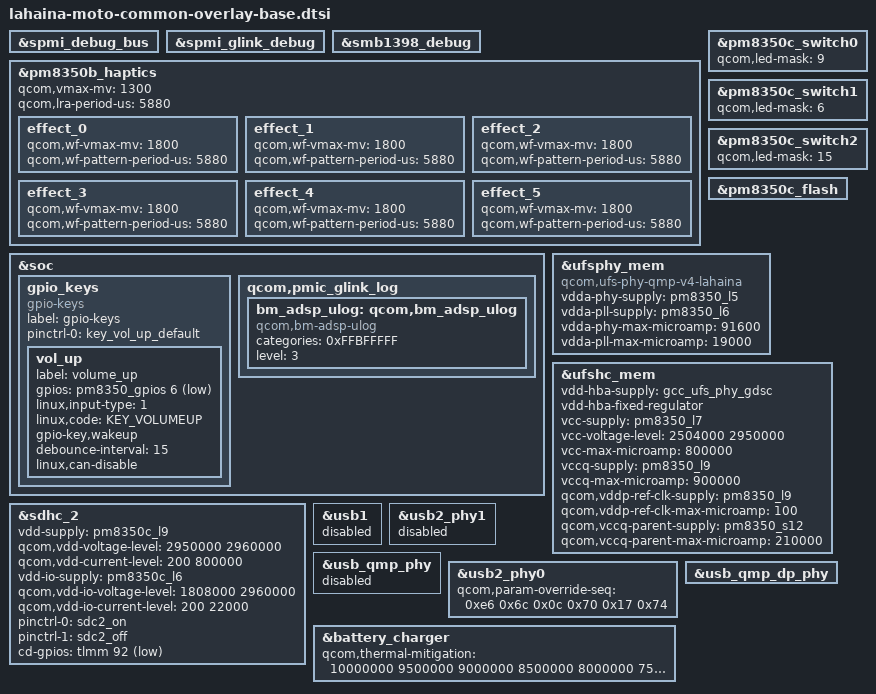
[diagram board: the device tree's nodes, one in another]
/* Copyright (c) 2020, The Linux Foundation. All rights reserved.
 *
 * This program is free software; you can redistribute it and/or modify
 * it under the terms of the GNU General Public License version 2 and
 * only version 2 as published by the Free Software Foundation.
 *
 * This program is distributed in the hope that it will be useful,
 * but WITHOUT ANY WARRANTY; without even the implied warranty of
 * MERCHANTABILITY or FITNESS FOR A PARTICULAR PURPOSE.  See the
 * GNU General Public License for more details.
 */

#include <dt-bindings/gpio/gpio.h>
#include <dt-bindings/input/input.h>

#include "lahaina-pmic-overlay.dtsi"
#include "lahaina-thermal-overlay.dtsi"

&spmi_debug_bus {
	status = "ok";
};

&spmi_glink_debug {
	status = "ok";
};

&smb1398_debug {
	status = "ok";
};

&pm8350b_haptics {
	qcom,vmax-mv = <1300>;
	qcom,lra-period-us = <5880>;
	status = "ok";

	effect_0 {
		/* CLICK */
		qcom,wf-vmax-mv = <1800>;
		qcom,wf-pattern-period-us = <5880>;
	};

	effect_1 {
		/* DOUBLE_CLICK */
		qcom,wf-vmax-mv = <1800>;
		qcom,wf-pattern-period-us = <5880>;
	};

	effect_2 {
		/* TICK */
		qcom,wf-vmax-mv = <1800>;
		qcom,wf-pattern-period-us = <5880>;
	};

	effect_3 {
		/* THUD */
		qcom,wf-vmax-mv = <1800>;
		qcom,wf-pattern-period-us = <5880>;
	};

	effect_4 {
		/* POP */
		qcom,wf-vmax-mv = <1800>;
		qcom,wf-pattern-period-us = <5880>;
	};

	effect_5 {
		/* HEAVY CLICK */
		qcom,wf-vmax-mv = <1800>;
		qcom,wf-pattern-period-us = <5880>;
	};
};

&soc {
	gpio_keys {
		compatible = "gpio-keys";
		label = "gpio-keys";

		pinctrl-names = "default";
		pinctrl-0 = <&key_vol_up_default>;

		vol_up {
			label = "volume_up";
			gpios = <&pm8350_gpios 6 GPIO_ACTIVE_LOW>;
			linux,input-type = <1>;
			linux,code = <KEY_VOLUMEUP>;
			gpio-key,wakeup;
			debounce-interval = <15>;
			linux,can-disable;
		};
	};

       qcom,pmic_glink_log {
               bm_adsp_ulog: qcom,bm_adsp_ulog {
                       compatible = "qcom,bm-adsp-ulog";
                       categories = <0xFFBFFFFF>;
                       level = <3>;
               };
       };

};

&pm8350c_switch0 {
	qcom,led-mask = <9>; /* Channels 1 & 4 */
};

&pm8350c_switch1 {
	qcom,led-mask = <6>; /* Channels 2 & 3 */
};

&pm8350c_switch2 {
	qcom,led-mask = <15>; /* All Channels */
};

&pm8350c_flash {
	status = "ok";
};

&ufsphy_mem {
	compatible = "qcom,ufs-phy-qmp-v4-lahaina";

	vdda-phy-supply = <&pm8350_l5>;
	vdda-pll-supply = <&pm8350_l6>;
	vdda-phy-max-microamp = <91600>;
	vdda-pll-max-microamp = <19000>;

	status = "ok";
};

&ufshc_mem {
	vdd-hba-supply = <&gcc_ufs_phy_gdsc>;
	vdd-hba-fixed-regulator;

	vcc-supply = <&pm8350_l7>;
	vcc-voltage-level = <2504000 2950000>;
	vcc-max-microamp = <800000>;

	vccq-supply = <&pm8350_l9>;
	vccq-max-microamp = <900000>;

	qcom,vddp-ref-clk-supply = <&pm8350_l9>;
	qcom,vddp-ref-clk-max-microamp = <100>;

	qcom,vccq-parent-supply = <&pm8350_s12>;
	qcom,vccq-parent-max-microamp = <210000>;

	status = "ok";
};

&sdhc_2 {
	vdd-supply = <&pm8350c_l9>;
	qcom,vdd-voltage-level = <2950000 2960000>;
	qcom,vdd-current-level = <200 800000>;

	vdd-io-supply = <&pm8350c_l6>;
	qcom,vdd-io-voltage-level = <1808000 2960000>;
	qcom,vdd-io-current-level = <200 22000>;

	pinctrl-names = "default", "sleep";
	pinctrl-0 = <&sdc2_on>;
	pinctrl-1 = <&sdc2_off>;

	cd-gpios = <&tlmm 92 GPIO_ACTIVE_LOW>;

	status = "ok";
};

&usb1 {
	status = "disabled";
};

&usb2_phy1 {
	status = "disabled";
};

&usb_qmp_phy {
	status = "disabled";
};

&usb2_phy0 {
	qcom,param-override-seq =
		<0xe6 0x6c
		0x0c 0x70
		0x17 0x74>;
};

&usb_qmp_dp_phy {
	pinctrl-names = "unused";
};

&battery_charger {
	qcom,thermal-mitigation = <10000000 9500000 9000000 8500000 8000000
				7500000 7000000 6500000 6000000 5500000
				5000000 4500000 4000000 3500000 3000000
				2500000 2000000 1500000 1000000 500000>;
};

